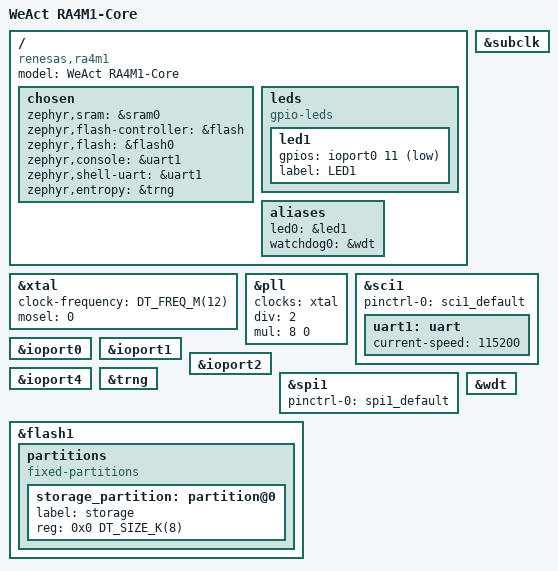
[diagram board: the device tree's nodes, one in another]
/*
 * Copyright (c) 2024-2025 Renesas Electronics Corporation
 * Copyright (c) 2025 Pete Johanson
 * Copyright (c) 2026 Henry Xin
 * SPDX-License-Identifier: Apache-2.0
 */

/dts-v1/;

#include <renesas/ra/ra4/r7fa4m1ab3cfm.dtsi>
#include <dt-bindings/gpio/gpio.h>
#include <zephyr/dt-bindings/adc/adc.h>
#include <dt-bindings/input/input-event-codes.h>
#include "ra4m1_core-pinctrl.dtsi"

/ {
	model = "WeAct RA4M1-Core";
	compatible = "renesas,ra4m1", "renesas,ra";

	chosen {
		zephyr,sram = &sram0;
        zephyr,flash-controller = &flash;
		zephyr,flash = &flash0;
		zephyr,console = &uart1;
		zephyr,shell-uart = &uart1;
		zephyr,entropy = &trng;
	};

	leds {
		compatible = "gpio-leds";

		led1: led1 {
			gpios = <&ioport0 11 GPIO_ACTIVE_LOW>;
			label = "LED1";
		};
	};

	aliases {
		led0 = &led1;
		watchdog0 = &wdt;
	};
};

&xtal {
	clock-frequency = <DT_FREQ_M(12)>;
	mosel = <0>;
	#clock-cells = <0>;
	status = "okay";
};

&subclk {
	status = "okay";
};

&pll {
	clocks = <&xtal>;
	div = <2>;
	mul = <8 0>;
	status = "okay";
};

&sci1 {
	pinctrl-0 = <&sci1_default>;
	pinctrl-names = "default";
	status = "okay";

	uart1: uart {
		current-speed = <115200>;
		status = "okay";
	};
};

&ioport0 {
	status = "okay";
};

&ioport1 {
	status = "okay";
};

&ioport2 {
	status = "okay";
};

&ioport4 {
	status = "okay";
};

&spi1 {
	pinctrl-0 = <&spi1_default>;
	pinctrl-names = "default";
	status = "okay";
};

&trng {
	status = "okay";
};

&wdt {
	status = "okay";
};

&flash1 {
	partitions {
		compatible = "fixed-partitions";
		#address-cells = <1>;
		#size-cells = <1>;

		storage_partition: partition@0 {
			label = "storage";
			reg = <0x0 DT_SIZE_K(8)>;
		};
	};
};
